# R5SS_TMU_EXT_CORE0_78060000h register map
Vendor: Texas Instruments
Peripheral module from a debugger description file (folder AM261x).
Registers are 32-bit, read-write, reset 0x0 unless marked. A register's access mark holds for its fields unless they carry their own. Offsets are as the file gives them; lines under a group give offsets from that group; [hi:lo] are bit positions; {n}, {i} and the like mark numbered series; 'fields as' and 'values as' point back to an identical list; <NAME> marks a mode.

## TMU_EXT_CORE0
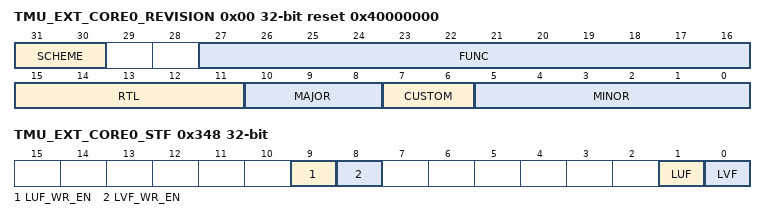
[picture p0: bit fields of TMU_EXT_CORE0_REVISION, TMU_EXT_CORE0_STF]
0x00 TMU_EXT_CORE0_REVISION ro reset 0x40000000 — IP revision id register.
  [31:30] SCHEME — This identifies the scheme revision ID register type implemented for this module
  [27:16] FUNC — Functional Release Number Reflects software-compatability. If there is no software compatability, a unique func number is assigned; for compatible modules, the same number is maintained.
  [15:11] RTL — Design Release Number Incremented for releases due to spec changes or post-release design changes. Reset to 0 when either MAJOR or MINOR is incremented.
  [10:8] MAJOR — Major Revision Number Represents major changes to the module [e.g. entirely new features are added/changed]. The major revision number for this module.
  [7:6] CUSTOM — Custom Module Number Indicates a special version of the module. May not be supported by standard software.
  [5:0] MINOR — Minor Revision Number Represents minor changes to the module [e.g. enhancements to existing features]. The minor revision number for this module.
{0x40+8i} TMU_EXT_CORE0_SINPUF32_R{i} (i=0..7) — Updates operand 1 for SINPUF32 operation. Result will be saved to R{i}.
  [31:0] SINPUF32_R{i} — Write to this register will update Operand 1 Update will trigger SINPUF32 operation Result will be saved to R{i} after 4 cycles
{0x80+8i} TMU_EXT_CORE0_COSPUF32_R{i} (i=0..7) — Updates operand 1 for COSPUF32 operation. Result will be saved to R{i}.
  [31:0] COSPUF32_R{i} — Write to this register will update Operand 1 Update will trigger COSPUF32 operation Result will be saved to R{i} after 4 cycles
{0xC0+8i} TMU_EXT_CORE0_ATANPUF32_R{i} (i=0..7) — Updates operand 1 for ATANPUF32 operation. Result will be saved to R{i}.
  [31:0] ATANPUF32_R{i} — Write to this register will update Operand 1 Update will trigger ATANPUF32 operation Result will be saved to R{i} after 4 cycles
{0x140+8i} TMU_EXT_CORE0_IEXP2F32_R{i} (i=0..7) — Updates operand 1 for IEXP2F32 operation. Result will be saved to R{i}.
  [31:0] IEXP2F32_R{i} — Write to this register will update Operand 1 Update will trigger IEXP2F32 operation Result will be saved to R{i} after 4 cycles
{0x180+8i} TMU_EXT_CORE0_LOG2F32_R{i} (i=0..7) — Updates operand 1 for LOG2F32 operation. Result will be saved to R{i}.
  [31:0] LOG2F32_R{i} — Write to this register will update Operand 1 Update will trigger LOG2F32 operation Result will be saved to R{i} after 4 cycles
{0x1C0+8i} TMU_EXT_CORE0_QUADF32_X_R{i}_R{i+1} (i=0..4) — Updates operand 1 (X) for QUADF32 operation. Result will be saved to R{i} and R{i+1}.
  [31:0] QUADF32_X_R{i}_R{i+1} — Write to this register will update Operand 1 Operand 2 must be written first by Writing to register QUADF32_Y Update will trigger QUADF32 operation Result will be saved to R{i} and R{i+1} after 5 cycles
0x1E8 TMU_EXT_CORE0_QUADF32_X_R5SS0_R6 — Updates operand 1 (X) for QUADF32 operation. Result will be saved to R5 and R6.
  [31:0] QUADF32_X_R5_R6 — Write to this register will update Operand 1 Operand 2 must be written first by Writing to register QUADF32_Y Update will trigger QUADF32 operation Result will be saved to R5 and R6 after 5 cycles
0x1F0 TMU_EXT_CORE0_QUADF32_X_R6_R7 — Updates operand 1 (X) for QUADF32 operation. Result will be saved to R6 and R7.
  [31:0] QUADF32_X_R6_R7 — Write to this register will update Operand 1 Operand 2 must be written first by Writing to register QUADF32_Y Update will trigger QUADF32 operation Result will be saved to R6 and R7 after 5 cycles
{0x280+8i} TMU_EXT_CORE0_RESULT_R{i} ro (i=0..7) — R{i} result register.
  [31:0] R{i} — R{i} result register
{0x2C0+8i} TMU_EXT_CORE0_CSAVE_R{i} ro (i=0..7) — Context save of R{i} result register.
  [31:0] CSAVE_R{i} — Context save of R{i} result register
0x300 TMU_EXT_CORE0_CSAVE_OP2 ro — Context save of Operarand2 result register.
  [31:0] CSAVE_OP2 — Context save of operand 2 [OP2] result register
0x308 TMU_EXT_CORE0_CONTEXT_SAVE access not given — Register to initiate context save of result registers.
  [0] SAVE — Writing one will initiate context save. Context save will be done only after completion all operations initiated by master before context save was issued. Results registers R0 to R3 and Operand2 will be saved. Note: Contex is saved within IP, not to external memory. (access R/W1TS)
0x310 TMU_EXT_CORE0_CONTEXT_RESTORE access not given — Register to initiate context restore of result registers.
  [0] RESTORE — Writing one will initiate context restore. Results registers R0 to R3 and Operand2 will be restored. (access R/W1TS)
0x348 TMU_EXT_CORE0_STF access per field — TMU status Register.
  [9] LUF_WR_EN ro — Always read as zero, Value is written to this bit either enables/disables write to LVF [[br]0:Disbles write to LUF 1:Enables write to LUF
  [8] LVF_WR_EN ro — Always read as zero, Value is written to this bit either enables/disables write to LVF [[br]0:Disbles write to LVF 1:Enables write to LVF
  [1] LUF rw — Is set to '1' when a TMU operation results in LVF. It is sticky bit, once set, it remains set until it is cleared with write. It can be written only when LUF_WR_EN Is written with '1'
  [0] LVF rw — Is set to '1' when a TMU operation results in LVF. It is sticky bit, once set, it remains set until it is cleared with write. It can be written only when LVF_WR_EN Is written with '1'
0x380 TMU_EXT_CORE0_PARITY_TEST — Enabling the parity test feature.
  [3:0] TESTEN — 1010: Parity test feature is enabled All other values: Parity test feature is disabled Note: When the parity test feature is enabled, acutal registers are not accessible in the memory map. Instead, the parity values are accessible. Parity is computed for every byte and the correponding parity value is available at the bit-0 of every byte. Value of '1' written to the parity bit after enabling the parity test feature can be used to inject the error by inverting the stored parity value.
0x390 TMU_EXT_CORE0_LCM_LOCK — LCM lock configuration.
  [0] PARITY_TEST — 0: Register configuration is not locked. [[br]1:Register configuration is locked.
0x3A0 TMU_EXT_CORE0_LCM_COMMIT access not given — LCM commit configuration.
  [0] PARITY_TEST — 0: Register lock configuration is not committed. [[br]1:Register lock configuration is committed. Once configuration is committed, only reset can change the configuration. (access R/W1TS)
